# S6E2DHxG register map
Vendor: Cypress; File version: 2.1
CPU: CM4 r0p1, little endian, MPU, FPU, 4 interrupt priority bits
Registers are 32-bit, read-write, reset 0x0 unless marked. A register's access mark holds for its fields unless they carry their own. Offsets are from the block's base; [hi:lo] are bit positions; {n}, {i} and the like mark numbered series.

## CANFD0 — CAN FD Registers
Base 0x40070000
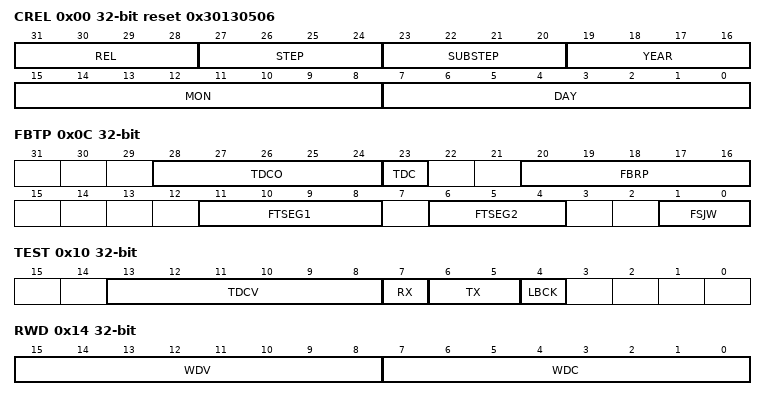
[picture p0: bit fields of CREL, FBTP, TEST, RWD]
0x00 CREL ro reset 0x30130506 — Core Release Register [BHW]
  [31:28] REL — Core Release
  [27:24] STEP — Step of Core Release
  [23:20] SUBSTEP — Sub-step of Core Release
  [19:16] YEAR — Time Stamp Year
  [15:8] MON — Time Stamp Month
  [7:0] DAY — Time Stamp Day
0x04 ENDN ro reset 0x87654321 — Endian Register [BHW]
  [31:0] ETV — Endianness Test Value
0x0C FBTP — Fast Bit Timing and Prescaler Register [BHW]
  [28:24] TDCO — Transceiver Delay Compensation Offset
  [23] TDC — Transceiver Delay Compensation
  [20:16] FBRP — Fast Baud Rate Prescaler
  [11:8] FTSEG1 — Fast time segment before sample point
  [6:4] FTSEG2 — Fast time segment after sample point
  [1:0] FSJW — Fast (Re) Synchronization Jump Width
0x10 TEST — Test Register [BHW]
  [13:8] TDCV ro — Transceiver Delay Compensation Value
  [7] RX — Receive Pin
  [6:5] TX — Control of Transmit Pin
  [4] LBCK — Loop Back Mode
0x14 RWD — RAM Watchdog [BHW]
  [15:8] WDV ro — Watchdog Value
  [7:0] WDC — Watchdog Configuration
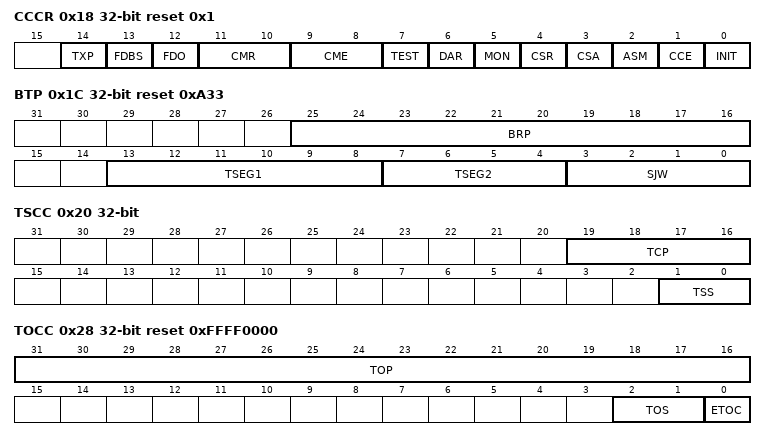
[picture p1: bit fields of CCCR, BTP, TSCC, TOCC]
0x18 CCCR reset 0x1 — CC Control Register [BHW]
  [14] TXP — Transmit Pause
  [13] FDBS ro — CAN FD Bit Rate Switching
  [12] FDO ro — CAN FD Operation
  [11:10] CMR — CAN Mode Request
  [9:8] CME — CAN Mode Enable
  [7] TEST — Test Mode Enable
  [6] DAR — Disable Automatic Retransmission
  [5] MON — Bus Monitoring Mode
  [4] CSR — Clock Stop Request
  [3] CSA ro — Clock Stop Acknowledge
  [2] ASM — Restricted Operation Mode
  [1] CCE — Configuration Change Enable
  [0] INIT — Initialization
0x1C BTP reset 0xA33 — Bit Timing and Prescaler Register [BHW]
  [25:16] BRP — Baud Rate Prescaler
  [13:8] TSEG1 — Time segment before sample point
  [7:4] TSEG2 — Time segment after sample point
  [3:0] SJW — (Re) Synchronization Jump Width
0x20 TSCC — Timestamp Counter Configuration [BHW]
  [19:16] TCP — Timestamp Counter Prescaler
  [1:0] TSS — Timestamp Select
0x24 TSCV — Timestamp Counter Value [BHW]
  [15:0] TSC — Timestamp Counter
0x28 TOCC reset 0xFFFF0000 — Timeout Counter Configuration [BHW]
  [31:16] TOP — Timeout Period
  [2:1] TOS — Timeout Select
  [0] ETOC — Enable Timeout Counter
0x2C TOCV reset 0xFFFF — Timeout Counter Value [BHW]
  [15:0] TOC — Timeout Counter
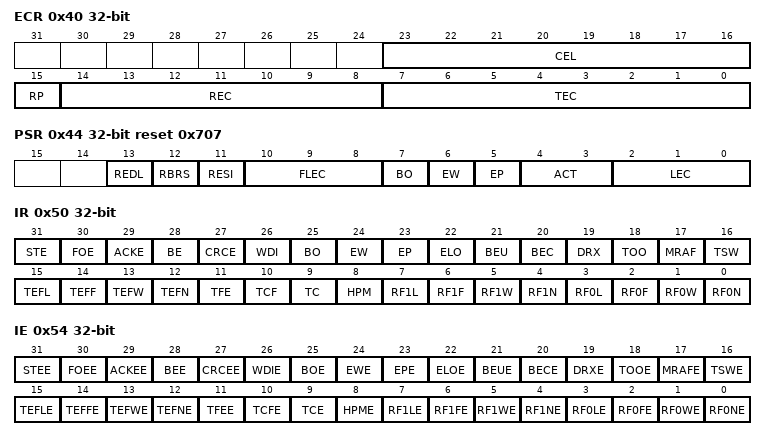
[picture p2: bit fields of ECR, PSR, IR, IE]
0x40 ECR ro — Error Counter Register [BHW]
  [23:16] CEL — CAN Error Logging
  [15] RP — Receive Error Passive
  [14:8] REC — Receive Error Counter
  [7:0] TEC — Transmit Error Counter
0x44 PSR ro reset 0x707 — Protocol Status Register [BHW]
  [13] REDL — Received a CAN FD Message
  [12] RBRS — BRS flag of last received CAN FD Message
  [11] RESI — ESI flag of last received CAN FD Message
  [10:8] FLEC — Fast Last Error Code
  [7] BO — Bus_Off Status
  [6] EW — Warning Status
  [5] EP — Error Passive
  [4:3] ACT — Activity
  [2:0] LEC — Last Error Code
0x50 IR — Interrupt Register [BHW]
  [31] STE — Stuff Error
  [30] FOE — Format Error
  [29] ACKE — Acknowledge Error
  [28] BE — Bit Error
  [27] CRCE — CRC Error
  [26] WDI — Watchdog Interrupt
  [25] BO — Bus_Off Status
  [24] EW — Warning Status
  [23] EP — Error Passive
  [22] ELO — Error Logging Overflow
  [21] BEU — Bit Error Uncorrected
  [20] BEC — Bit Error Corrected
  [19] DRX — Message stored to Dedicated Rx Buffer
  [18] TOO — Timeout Occurred
  [17] MRAF — Message RAM Access Failure
  [16] TSW — Timestamp Wraparound
  [15] TEFL — Tx Event FIFO Element Lost
  [14] TEFF — Tx Event FIFO Full
  [13] TEFW — Tx Event FIFO Watermark Reached
  [12] TEFN — Tx Event FIFO New Entry
  [11] TFE — Tx FIFO Empty
  [10] TCF — Transmission Cancellation Finished
  [9] TC — Transmission Completed
  [8] HPM — High Priority Message
  [7] RF1L — Rx FIFO 1 Message Lost
  [6] RF1F — Rx FIFO 1 Full
  [5] RF1W — Rx FIFO 1 Watermark Reached
  [4] RF1N — Rx FIFO 1 New Message
  [3] RF0L — Rx FIFO 0 Message Lost
  [2] RF0F — Rx FIFO 0 Full
  [1] RF0W — Rx FIFO 0 Watermark Reached
  [0] RF0N — Rx FIFO 0 New Message
0x54 IE — Interrupt Enable [BHW]
  [31] STEE — Stuff Error Interrupt Enable
  [30] FOEE — Format Error Interrupt Enable
  [29] ACKEE — Acknowledge Error Interrupt Enable
  [28] BEE — Bit Error Interrupt Enable
  [27] CRCEE — CRC Error Interrupt Enable
  [26] WDIE — Watchdog Interrupt Interrupt Enable
  [25] BOE — Bus_Off Status Interrupt Enable
  [24] EWE — Warning Status Interrupt Enable
  [23] EPE — Error Passive Interrupt Enable
  [22] ELOE — Error Logging Overflow Interrupt Enable
  [21] BEUE — Bit Error Uncorrected Interrupt Enable
  [20] BECE — Bit Error Corrected Interrupt Enable
  [19] DRXE — Message stored to Dedicated Rx Buffer Interrupt Enable
  [18] TOOE — Timeout Occurred Interrupt Enable
  [17] MRAFE — Message RAM Access Failure Interrupt Enable
  [16] TSWE — Timestamp Wraparound Interrupt Enable
  [15] TEFLE — Tx Event FIFO Element Lost Interrupt Enable
  [14] TEFFE — Tx Event FIFO Full Interrupt Enable
  [13] TEFWE — Tx Event FIFO Watermark Reached Interrupt Enable
  [12] TEFNE — Tx Event FIFO New Entry Interrupt Enable
  [11] TFEE — Tx FIFO Empty Interrupt Enable
  [10] TCFE — Transmission Cancellation Finished Interrupt Enable
  [9] TCE — Transmission Completed Interrupt Enable
  [8] HPME — High Priority Message Interrupt Enable
  [7] RF1LE — Rx FIFO 1 Message Lost Interrupt Enable
  [6] RF1FE — Rx FIFO 1 Full Interrupt Enable
  [5] RF1WE — Rx FIFO 1 Watermark Reached Interrupt Enable
  [4] RF1NE — Rx FIFO 1 New Message Interrupt Enable
  [3] RF0LE — Rx FIFO 0 Message Lost Interrupt Enable
  [2] RF0FE — Rx FIFO 0 Full Interrupt Enable
  [1] RF0WE — Rx FIFO 0 Watermark Reached Interrupt Enable
  [0] RF0NE — Rx FIFO 0 New Message Interrupt Enable
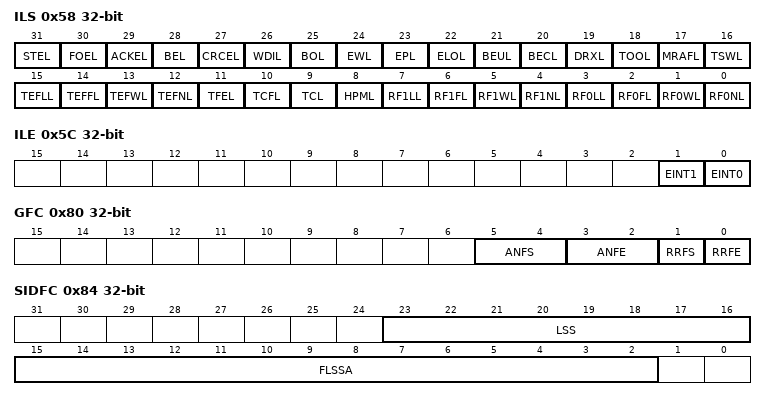
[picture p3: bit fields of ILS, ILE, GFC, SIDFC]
0x58 ILS — Interrupt Line Select [BHW]
  [31] STEL — Stuff Error Interrupt Line
  [30] FOEL — Format Error Interrupt Line
  [29] ACKEL — Acknowledge Error Interrupt Line
  [28] BEL — Bit Error Interrupt Line
  [27] CRCEL — CRC Error Interrupt Line
  [26] WDIL — Watchdog Interrupt Interrupt Line
  [25] BOL — Bus_Off Status Interrupt Line
  [24] EWL — Warning Status Interrupt Line
  [23] EPL — Error Passive Interrupt Line
  [22] ELOL — Error Logging Overflow Interrupt Line
  [21] BEUL — Bit Error Uncorrected Interrupt Line
  [20] BECL — Bit Error Corrected Interrupt Line
  [19] DRXL — Message stored to Dedicated Rx Buffer Interrupt Line
  [18] TOOL — Timeout Occurred Interrupt Line
  [17] MRAFL — Message RAM Access Failure Interrupt Line
  [16] TSWL — Timestamp Wraparound Interrupt Line
  [15] TEFLL — Tx Event FIFO Element Lost Interrupt Line
  [14] TEFFL — Tx Event FIFO Full Interrupt Line
  [13] TEFWL — Tx Event FIFO Watermark Reached Interrupt Line
  [12] TEFNL — Tx Event FIFO New Entry Interrupt Line
  [11] TFEL — Tx FIFO Empty Interrupt Line
  [10] TCFL — Transmission Cancellation Finished Interrupt Line
  [9] TCL — Transmission Completed Interrupt Line
  [8] HPML — High Priority Message Interrupt Line
  [7] RF1LL — Rx FIFO 1 Message Lost Interrupt Line
  [6] RF1FL — Rx FIFO 1 Full Interrupt Line
  [5] RF1WL — Rx FIFO 1 Watermark Reached Interrupt Line
  [4] RF1NL — Rx FIFO 1 New Message Interrupt Line
  [3] RF0LL — Rx FIFO 0 Message Lost Interrupt Line
  [2] RF0FL — Rx FIFO 0 Full Interrupt Line
  [1] RF0WL — Rx FIFO 0 Watermark Reached Interrupt Line
  [0] RF0NL — Rx FIFO 0 New Message Interrupt Line
0x5C ILE — Interrupt Line Enable [BHW]
  [1] EINT1 — Enable Interrupt Line 1
  [0] EINT0 — Enable Interrupt Line 0
0x80 GFC — Global Filter Configuration [BHW]
  [5:4] ANFS — Accept Non-matching Frames Standard
  [3:2] ANFE — Accept Non-matching Frames Extended
  [1] RRFS — Reject Remote Frames Standard
  [0] RRFE — Reject Remote Frames Extended
0x84 SIDFC — Standard ID Filter Configuration [BHW]
  [23:16] LSS — List Size Standard
  [15:2] FLSSA — Filter List Standard Start Address
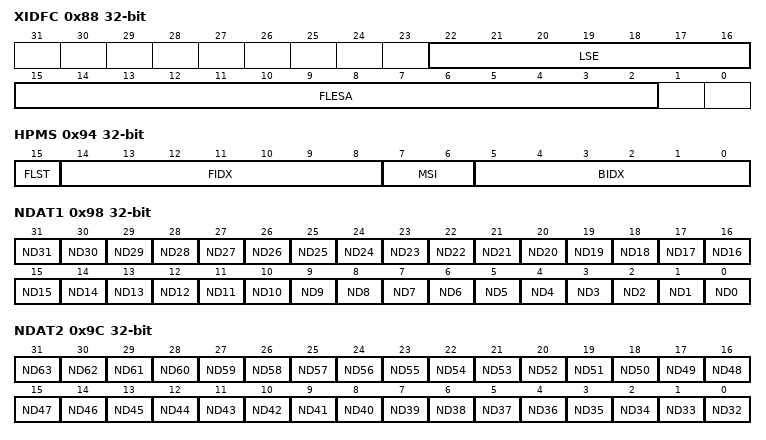
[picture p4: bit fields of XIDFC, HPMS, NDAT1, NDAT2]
0x88 XIDFC — Extended ID Filter Configuration [BHW]
  [22:16] LSE — List Size Extended
  [15:2] FLESA — Filter List Extended Start Address
0x90 XIDAM reset 0x1FFFFFFF — Extended ID AND Mask [BHW]
  [28:0] EIDM — Extended ID Mask
0x94 HPMS ro — High Priority Message Status [BHW]
  [15] FLST — Filter List
  [14:8] FIDX — Filter Index
  [7:6] MSI — Message Storage Indicator
  [5:0] BIDX — Buffer Index
0x98 NDAT1 ro — New Data 1 [BHW]
  [n] ND{n} rw (n=0..31) — New Data flag of Rx Buffer {n}
0x9C NDAT2 ro — New Data 2 [BHW]
  [n-32] ND{n} rw (n=32..63) — New Data flag of Rx Buffer {n}
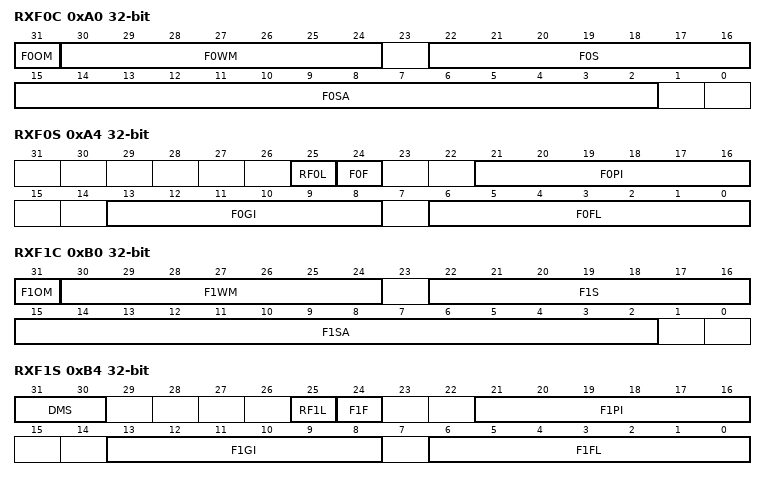
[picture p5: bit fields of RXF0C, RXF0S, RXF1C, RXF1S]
0xA0 RXF0C — Rx FIFO 0 Configuration [BHW]
  [31] F0OM — FIFO 0 Operation Mode
  [30:24] F0WM — Rx FIFO 0 Watermark
  [22:16] F0S — Rx FIFO 0 Size
  [15:2] F0SA — Rx FIFO 0 Start Address
0xA4 RXF0S ro — Rx FIFO 0 Status [BHW]
  [25] RF0L — Rx FIFO 0 Message Lost
  [24] F0F — Rx FIFO 0 Full
  [21:16] F0PI — Rx FIFO 0 Put Index
  [13:8] F0GI — Rx FIFO 0 Get Index
  [6:0] F0FL — Rx FIFO 0 Fill Level
0xA8 RXF0A — Rx FIFO 0 Acknowledge [BHW]
  [5:0] F0AI — Rx FIFO 0 Acknowledge Index
0xAC RXBC — Rx Buffer Configuration [BHW]
  [15:2] RBSA — 2
0xB0 RXF1C — Rx FIFO 1 Configuration [BHW]
  [31] F1OM — FIFO 1 Operation Mode
  [30:24] F1WM — Rx FIFO 1 Watermark
  [22:16] F1S — Rx FIFO 1 Size
  [15:2] F1SA — Rx FIFO 1 Start Address
0xB4 RXF1S ro — Rx FIFO 1 Status [BHW]
  [31:30] DMS — Debug Message Status
  [25] RF1L — FIFO 1 Message Lost
  [24] F1F — Rx FIFO 1 Full
  [21:16] F1PI — Rx FIFO 1 Put Index
  [13:8] F1GI — Rx FIFO 1 Get Index
  [6:0] F1FL — Rx FIFO 1 Fill Level
0xB8 RXF1A — Rx FIFO 1 Acknowledge [BHW]
  [5:0] F1AI — Rx FIFO 1 Acknowledge Index
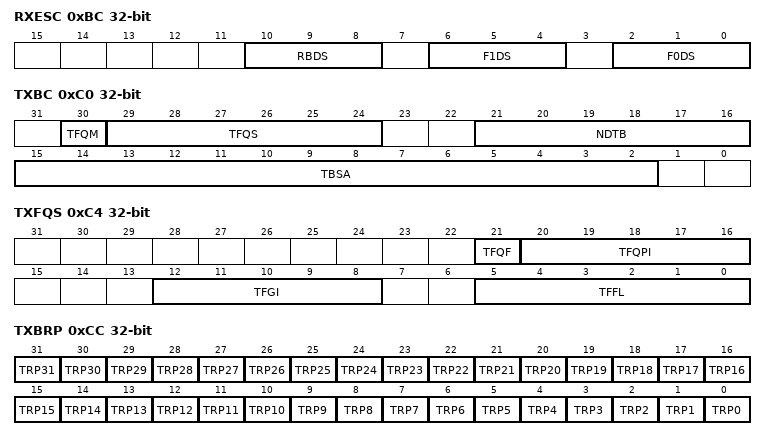
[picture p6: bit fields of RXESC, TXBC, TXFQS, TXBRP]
0xBC RXESC — Rx Buffer/FIFO Element Size Configuration [BHW]
  [10:8] RBDS — Rx Buffer Data Field Size
  [6:4] F1DS — Rx FIFO 1 Data Field Size
  [2:0] F0DS — Rx FIFO 0 Data Field Size
0xC0 TXBC — Tx Buffer Configuration [BHW]
  [30] TFQM — Tx FIFO/Queue Mode
  [29:24] TFQS — Transmit FIFO/Queue Size
  [21:16] NDTB — Number of Dedicated Transmit Buffers
  [15:2] TBSA — Tx Buffers Start Address
0xC4 TXFQS ro — Tx FIFO/Queue Status [BHW]
  [21] TFQF — Tx FIFO/Queue Full
  [20:16] TFQPI — Tx FIFO/Queue Put Index
  [12:8] TFGI — Tx FIFO Get Index
  [5:0] TFFL — Tx FIFO Free Level
0xC8 TXESC ro — Tx Buffer Element Size Configuration [BHW]
  [2:0] TBDS rw — Tx Buffer Data Field Size
0xCC TXBRP ro — Tx Buffer Request Pending [BHW]
  [n] TRP{n} (n=0..31) — Transmission Request Pending of Tx Buffer {n}
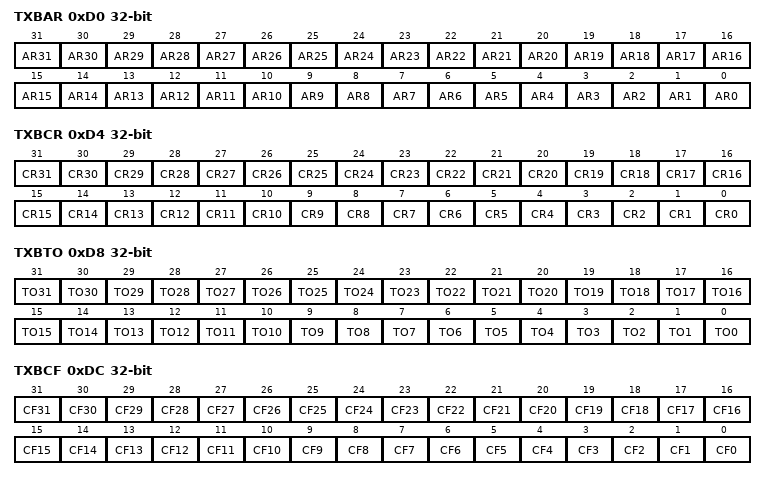
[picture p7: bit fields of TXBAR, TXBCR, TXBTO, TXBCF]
0xD0 TXBAR — Tx Buffer Add Request [BHW]
  [n] AR{n} (n=0..31) — Add Request of Tx Buffer {n}
0xD4 TXBCR — Tx Buffer Cancellation Request [BHW]
  [n] CR{n} (n=0..31) — Cancellation Request of Tx Buffer {n}
0xD8 TXBTO ro — Tx Buffer Transmission Occurred [BHW]
  [n] TO{n} (n=0..31) — Transmission Occurred of Tx Buffer {n}
0xDC TXBCF ro — Tx Buffer Cancellation Finished [BHW]
  [n] CF{n} (n=0..31) — Cancellation Finished of Tx Buffer {n}
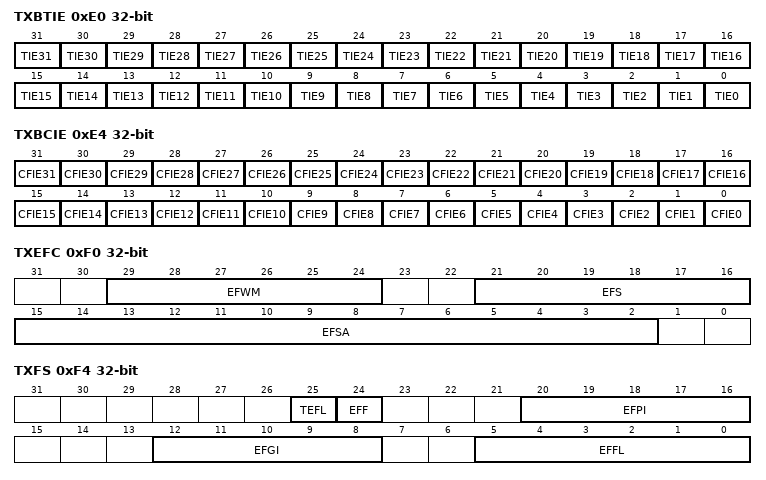
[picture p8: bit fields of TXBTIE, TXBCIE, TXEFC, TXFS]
0xE0 TXBTIE — Tx Buffer Transmission Interrupt Enable [BHW]
  [n] TIE{n} (n=0..31) — Transmission Interrupt Enable of Tx Buffer {n}
0xE4 TXBCIE — Tx Buffer Cancellation Finished Interrupt Enable [BHW]
  [n] CFIE{n} (n=0..31) — Cancellation Finished Interrupt Enable of Tx Buffer {n}
0xF0 TXEFC — Tx Event FIFO Configuration [BHW]
  [29:24] EFWM — Event FIFO Watermark
  [21:16] EFS — Event FIFO Size
  [15:2] EFSA — Event FIFO Start Address
0xF4 TXFS ro — Tx Event FIFO Status [BHW]
  [25] TEFL — Tx Event FIFO Element Lost
  [24] EFF — Event FIFO Full
  [20:16] EFPI — Event FIFO Put Index
  [12:8] EFGI — Event FIFO Get Index
  [5:0] EFFL — Event FIFO Fill Level
0xF8 TXFA — Tx Event FIFO Acknowledge [BHW]
  [4:0] EFAI — Event FIFO Acknowledge Index
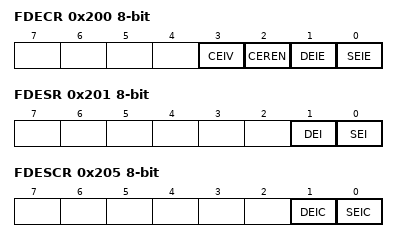
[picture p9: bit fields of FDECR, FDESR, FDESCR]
0x200 FDECR 8-bit — CAN FD ECC Error Control Register [BHW]
  [3] CEIV — ECC check disable bit
  [2] CEREN — ECC error response enable bit
  [1] DEIE — Double-bit error factor interrupt enable bit
  [0] SEIE — Single-bit error factor interrupt enable bit
0x201 FDESR 8-bit ro — CAN FD ECC Error Status Register [BHW]
  [1] DEI — Double-bit error occurrence bit
  [0] SEI — Single-bit error occurrence bit
0x202 FDSEAR 16-bit ro — CAN FD ECC Single-bit Error Address Register [BHW]
  [15:0] SRA — Single-bit error Message RAM address bits
0x205 FDESCR 8-bit wo — CAN FD ECC Error Status Clear Register [BHW]
  [1] DEIC — Double-bit error clear bit
  [0] SEIC — Sngle-bit error clear bit
0x206 FDDEAR 16-bit ro — CAN FD ECC Double-bit Error Address Register [BHW]
  [15:0] DRA — Double-bit error Message RAM address bits
0x210 TSCNTR 16-bit wo — Time Stamp Control Register [BHW]
  [0] CCLR — Counter clear bit
0x212 TSMDR 16-bit — Time Stamp Mode Register [BHW]
  [0] CNTEN — Counter enable bit
0x214 TSDIVR — Time Stamp Divider Register [BHW]
  [15:0] CDIV — Counter clock division ratio setting bit
0x218 TSCDTR 16-bit ro — Time Stamp Counter Data Register [BHW]
  [15:0] CNT — Counter value bits
0x21A TSCPCLR 16-bit — Time Stamp Compare Clear Register [BHW]
  [15:0] CMP — Compare clear setting bits
